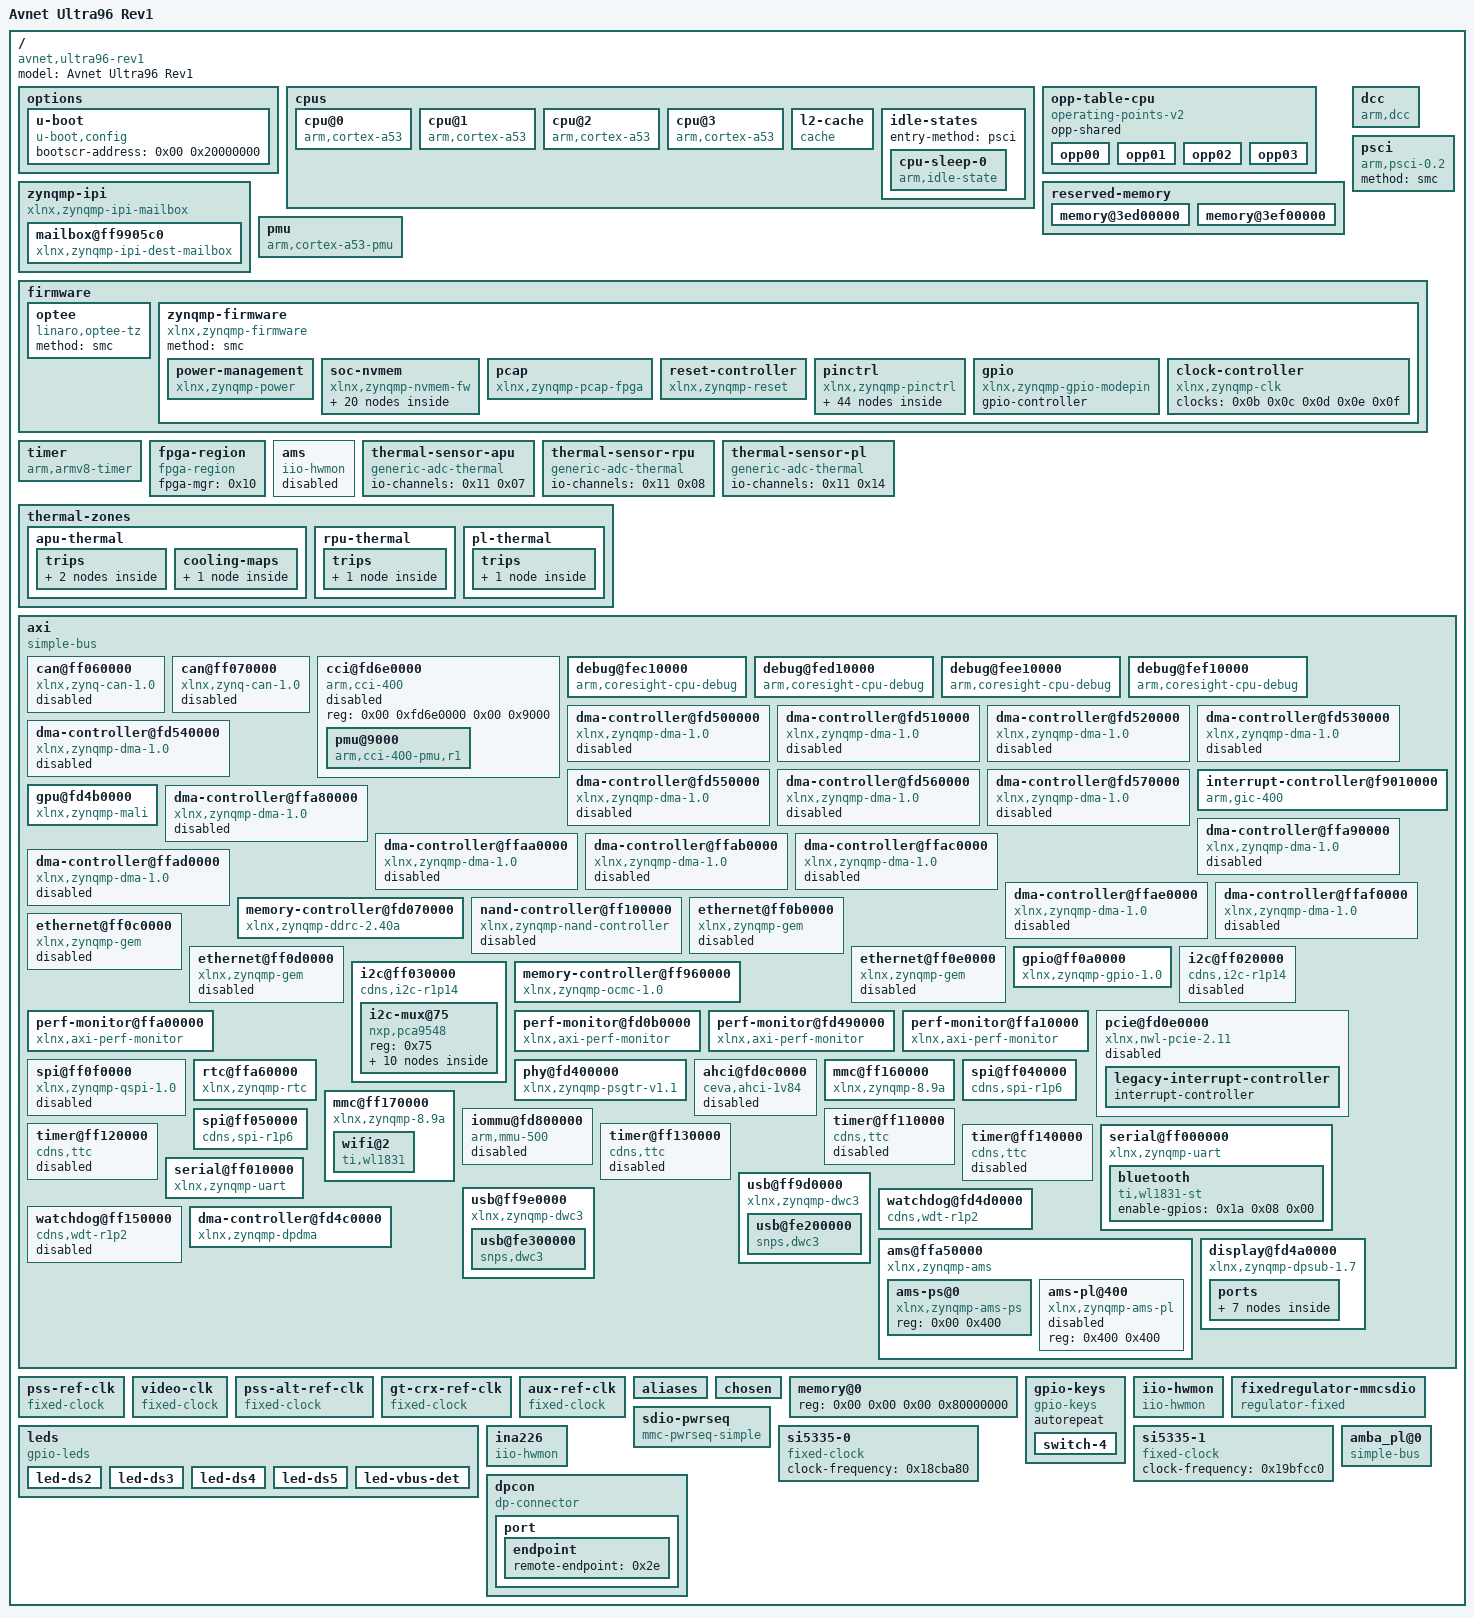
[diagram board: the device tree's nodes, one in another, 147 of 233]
/dts-v1/;

/ {
	compatible = "avnet,ultra96-rev1\0avnet,ultra96\0xlnx,zynqmp-zcu100-revC\0xlnx,zynqmp-zcu100\0xlnx,zynqmp";
	#address-cells = <0x02>;
	#size-cells = <0x02>;
	model = "Avnet Ultra96 Rev1";

	options {

		u-boot {
			compatible = "u-boot,config";
			bootscr-address = <0x00 0x20000000>;
		};
	};

	cpus {
		#address-cells = <0x01>;
		#size-cells = <0x00>;

		cpu@0 {
			#cooling-cells = <0x02>;
			compatible = "arm,cortex-a53";
			device_type = "cpu";
			enable-method = "psci";
			operating-points-v2 = <0x01>;
			reg = <0x00>;
			cpu-idle-states = <0x02>;
			next-level-cache = <0x03>;
			clocks = <0x04 0x0a>;
			phandle = <0x06>;
		};

		cpu@1 {
			#cooling-cells = <0x02>;
			compatible = "arm,cortex-a53";
			device_type = "cpu";
			enable-method = "psci";
			reg = <0x01>;
			operating-points-v2 = <0x01>;
			cpu-idle-states = <0x02>;
			next-level-cache = <0x03>;
			phandle = <0x07>;
		};

		cpu@2 {
			#cooling-cells = <0x02>;
			compatible = "arm,cortex-a53";
			device_type = "cpu";
			enable-method = "psci";
			reg = <0x02>;
			operating-points-v2 = <0x01>;
			cpu-idle-states = <0x02>;
			next-level-cache = <0x03>;
			phandle = <0x08>;
		};

		cpu@3 {
			#cooling-cells = <0x02>;
			compatible = "arm,cortex-a53";
			device_type = "cpu";
			enable-method = "psci";
			reg = <0x03>;
			operating-points-v2 = <0x01>;
			cpu-idle-states = <0x02>;
			next-level-cache = <0x03>;
			phandle = <0x09>;
		};

		l2-cache {
			compatible = "cache";
			cache-level = <0x02>;
			cache-unified;
			phandle = <0x03>;
		};

		idle-states {
			entry-method = "psci";

			cpu-sleep-0 {
				compatible = "arm,idle-state";
				arm,psci-suspend-param = <0x40000000>;
				local-timer-stop;
				entry-latency-us = <0x12c>;
				exit-latency-us = <0x258>;
				min-residency-us = <0x2710>;
				phandle = <0x02>;
			};
		};
	};

	opp-table-cpu {
		compatible = "operating-points-v2";
		opp-shared;
		phandle = <0x01>;

		opp00 {
			opp-hz = <0x00 0x47868bf4>;
			opp-microvolt = <0xf4240>;
			clock-latency-ns = <0x7a120>;
		};

		opp01 {
			opp-hz = <0x00 0x23c345fa>;
			opp-microvolt = <0xf4240>;
			clock-latency-ns = <0x7a120>;
		};

		opp02 {
			opp-hz = <0x00 0x17d783fc>;
			opp-microvolt = <0xf4240>;
			clock-latency-ns = <0x7a120>;
		};

		opp03 {
			opp-hz = <0x00 0x11e1a2fd>;
			opp-microvolt = <0xf4240>;
			clock-latency-ns = <0x7a120>;
		};
	};

	reserved-memory {
		#address-cells = <0x02>;
		#size-cells = <0x02>;
		ranges;

		memory@3ed00000 {
			no-map;
			reg = <0x00 0x3ed00000 0x00 0x40000>;
			phandle = <0x2f>;
		};

		memory@3ef00000 {
			no-map;
			reg = <0x00 0x3ef00000 0x00 0x40000>;
			phandle = <0x30>;
		};
	};

	zynqmp-ipi {
		bootph-all;
		compatible = "xlnx,zynqmp-ipi-mailbox";
		interrupt-parent = <0x05>;
		interrupts = <0x00 0x23 0x04>;
		xlnx,ipi-id = <0x00>;
		#address-cells = <0x02>;
		#size-cells = <0x02>;
		ranges;
		phandle = <0x31>;

		mailbox@ff9905c0 {
			bootph-all;
			compatible = "xlnx,zynqmp-ipi-dest-mailbox";
			reg = <0x00 0xff9905c0 0x00 0x20 0x00 0xff9905e0 0x00 0x20 0x00 0xff990e80 0x00 0x20 0x00 0xff990ea0 0x00 0x20>;
			reg-names = "local_request_region\0local_response_region\0remote_request_region\0remote_response_region";
			#mbox-cells = <0x01>;
			xlnx,ipi-id = <0x04>;
			phandle = <0x0a>;
		};
	};

	dcc {
		compatible = "arm,dcc";
		status = "okay";
		bootph-all;
		phandle = <0x32>;
	};

	pmu {
		compatible = "arm,cortex-a53-pmu";
		interrupt-parent = <0x05>;
		interrupts = <0x00 0x8f 0x04 0x00 0x90 0x04 0x00 0x91 0x04 0x00 0x92 0x04>;
		interrupt-affinity = <0x06 0x07 0x08 0x09>;
	};

	psci {
		compatible = "arm,psci-0.2";
		method = "smc";
	};

	firmware {

		optee {
			compatible = "linaro,optee-tz";
			method = "smc";
			phandle = <0x33>;
		};

		zynqmp-firmware {
			compatible = "xlnx,zynqmp-firmware";
			#power-domain-cells = <0x01>;
			method = "smc";
			bootph-all;
			phandle = <0x17>;

			power-management {
				bootph-all;
				compatible = "xlnx,zynqmp-power";
				interrupt-parent = <0x05>;
				interrupts = <0x00 0x23 0x04>;
				mboxes = <0x0a 0x00 0x0a 0x01>;
				mbox-names = "tx\0rx";
				phandle = <0x34>;
			};

			soc-nvmem {
				compatible = "xlnx,zynqmp-nvmem-fw";

				nvmem-layout {
					compatible = "fixed-layout";
					#address-cells = <0x01>;
					#size-cells = <0x01>;

					soc-revision@0 {
						reg = <0x00 0x04>;
						phandle = <0x35>;
					};

					efuse-dna@c {
						reg = <0x0c 0x0c>;
						phandle = <0x36>;
					};

					efuse-usr0@20 {
						reg = <0x20 0x04>;
						phandle = <0x37>;
					};

					efuse-usr1@24 {
						reg = <0x24 0x04>;
						phandle = <0x38>;
					};

					efuse-usr2@28 {
						reg = <0x28 0x04>;
						phandle = <0x39>;
					};

					efuse-usr3@2c {
						reg = <0x2c 0x04>;
						phandle = <0x3a>;
					};

					efuse-usr4@30 {
						reg = <0x30 0x04>;
						phandle = <0x3b>;
					};

					efuse-usr5@34 {
						reg = <0x34 0x04>;
						phandle = <0x3c>;
					};

					efuse-usr6@38 {
						reg = <0x38 0x04>;
						phandle = <0x3d>;
					};

					efuse-usr7@3c {
						reg = <0x3c 0x04>;
						phandle = <0x3e>;
					};

					efuse-miscusr@40 {
						reg = <0x40 0x04>;
						phandle = <0x3f>;
					};

					efuse-chash@50 {
						reg = <0x50 0x04>;
						phandle = <0x40>;
					};

					efuse-pufmisc@54 {
						reg = <0x54 0x04>;
						phandle = <0x41>;
					};

					efuse-sec@58 {
						reg = <0x58 0x04>;
						phandle = <0x42>;
					};

					efuse-spkid@5c {
						reg = <0x5c 0x04>;
						phandle = <0x43>;
					};

					efuse-aeskey@60 {
						reg = <0x60 0x20>;
						phandle = <0x44>;
					};

					efuse-ppk0hash@a0 {
						reg = <0xa0 0x30>;
						phandle = <0x45>;
					};

					efuse-ppk1hash@d0 {
						reg = <0xd0 0x30>;
						phandle = <0x46>;
					};

					efuse-pufuser@100 {
						reg = <0x100 0x7f>;
						phandle = <0x47>;
					};
				};
			};

			pcap {
				compatible = "xlnx,zynqmp-pcap-fpga";
				phandle = <0x10>;
			};

			reset-controller {
				compatible = "xlnx,zynqmp-reset";
				#reset-cells = <0x01>;
				phandle = <0x16>;
			};

			pinctrl {
				compatible = "xlnx,zynqmp-pinctrl";
				status = "okay";
				phandle = <0x48>;

				i2c1-default {
					phandle = <0x18>;

					mux {
						groups = "i2c1_1_grp";
						function = "i2c1";
					};

					conf {
						groups = "i2c1_1_grp";
						bias-pull-up;
						slew-rate = <0x01>;
						power-source = <0x01>;
					};
				};

				i2c1-gpio-grp {
					phandle = <0x19>;

					mux {
						groups = "gpio0_4_grp\0gpio0_5_grp";
						function = "gpio0";
					};

					conf {
						groups = "gpio0_4_grp\0gpio0_5_grp";
						slew-rate = <0x01>;
						power-source = <0x01>;
					};
				};

				sdhci0-default {
					phandle = <0x1f>;

					mux {
						groups = "sdio0_3_grp";
						function = "sdio0";
					};

					conf {
						groups = "sdio0_3_grp";
						slew-rate = <0x01>;
						power-source = <0x01>;
						bias-disable;
					};

					mux-cd {
						groups = "sdio0_cd_0_grp";
						function = "sdio0_cd";
					};

					conf-cd {
						groups = "sdio0_cd_0_grp";
						bias-high-impedance;
						bias-pull-up;
						slew-rate = <0x01>;
						power-source = <0x01>;
					};
				};

				sdhci1-default {
					phandle = <0x20>;

					mux {
						groups = "sdio1_2_grp";
						function = "sdio1";
					};

					conf {
						groups = "sdio1_2_grp";
						slew-rate = <0x01>;
						power-source = <0x01>;
						bias-disable;
					};
				};

				spi0-default {
					phandle = <0x23>;

					mux {
						groups = "spi0_3_grp";
						function = "spi0";
					};

					conf {
						groups = "spi0_3_grp";
						bias-disable;
						slew-rate = <0x01>;
						power-source = <0x01>;
					};

					mux-cs {
						groups = "spi0_ss_9_grp";
						function = "spi0_ss";
					};

					conf-cs {
						groups = "spi0_ss_9_grp";
						bias-disable;
					};
				};

				spi1-default {
					phandle = <0x24>;

					mux {
						groups = "spi1_0_grp";
						function = "spi1";
					};

					conf {
						groups = "spi1_0_grp";
						bias-disable;
						slew-rate = <0x01>;
						power-source = <0x01>;
					};

					mux-cs {
						groups = "spi1_ss_0_grp";
						function = "spi1_ss";
					};

					conf-cs {
						groups = "spi1_ss_0_grp";
						bias-disable;
					};
				};

				uart0-default {
					phandle = <0x25>;

					mux {
						groups = "uart0_0_grp";
						function = "uart0";
					};

					conf {
						groups = "uart0_0_grp";
						slew-rate = <0x01>;
						power-source = <0x01>;
					};

					conf-rx {
						pins = "MIO3";
						bias-high-impedance;
					};

					conf-tx {
						pins = "MIO2";
						bias-disable;
					};
				};

				uart1-default {
					phandle = <0x26>;

					mux {
						groups = "uart1_0_grp";
						function = "uart1";
					};

					conf {
						groups = "uart1_0_grp";
						slew-rate = <0x01>;
						power-source = <0x01>;
					};

					conf-rx {
						pins = "MIO1";
						bias-high-impedance;
					};

					conf-tx {
						pins = "MIO0";
						bias-disable;
					};
				};

				usb0-default {
					phandle = <0x27>;

					mux {
						groups = "usb0_0_grp";
						function = "usb0";
					};

					conf {
						groups = "usb0_0_grp";
						power-source = <0x01>;
					};

					conf-rx {
						pins = "MIO52\0MIO53\0MIO55";
						bias-high-impedance;
						drive-strength = <0x0c>;
						slew-rate = <0x00>;
					};

					conf-tx {
						pins = "MIO54\0MIO56\0MIO57\0MIO58\0MIO59\0MIO60\0MIO61\0MIO62\0MIO63";
						bias-disable;
						drive-strength = <0x04>;
						slew-rate = <0x01>;
					};
				};

				usb1-default {
					phandle = <0x29>;

					mux {
						groups = "usb1_0_grp";
						function = "usb1";
					};

					conf {
						groups = "usb1_0_grp";
						power-source = <0x01>;
					};

					conf-rx {
						pins = "MIO64\0MIO65\0MIO67";
						bias-high-impedance;
						drive-strength = <0x0c>;
						slew-rate = <0x00>;
					};

					conf-tx {
						pins = "MIO66\0MIO68\0MIO69\0MIO70\0MIO71\0MIO72\0MIO73\0MIO74\0MIO75";
						bias-disable;
						drive-strength = <0x04>;
						slew-rate = <0x01>;
					};
				};
			};

			gpio {
				compatible = "xlnx,zynqmp-gpio-modepin";
				gpio-controller;
				#gpio-cells = <0x02>;
				phandle = <0x2a>;
			};

			clock-controller {
				bootph-all;
				#clock-cells = <0x01>;
				compatible = "xlnx,zynqmp-clk";
				clocks = <0x0b 0x0c 0x0d 0x0e 0x0f>;
				clock-names = "pss_ref_clk\0video_clk\0pss_alt_ref_clk\0aux_ref_clk\0gt_crx_ref_clk";
				phandle = <0x04>;
			};
		};
	};

	timer {
		compatible = "arm,armv8-timer";
		interrupt-parent = <0x05>;
		interrupts = <0x01 0x0d 0xf08 0x01 0x0e 0xf08 0x01 0x0b 0xf08 0x01 0x0a 0xf08>;
	};

	fpga-region {
		compatible = "fpga-region";
		fpga-mgr = <0x10>;
		#address-cells = <0x02>;
		#size-cells = <0x02>;
		ranges;
		phandle = <0x49>;
	};

	ams {
		compatible = "iio-hwmon";
		status = "disabled";
		io-channels = <0x11 0x00 0x11 0x01 0x11 0x02 0x11 0x03 0x11 0x04 0x11 0x05 0x11 0x06 0x11 0x07 0x11 0x08 0x11 0x09 0x11 0x0a 0x11 0x0b 0x11 0x0c 0x11 0x0d 0x11 0x0e 0x11 0x0f 0x11 0x10 0x11 0x11 0x11 0x12 0x11 0x13 0x11 0x14 0x11 0x15 0x11 0x16 0x11 0x17 0x11 0x18 0x11 0x19 0x11 0x1a 0x11 0x1b 0x11 0x1c 0x11 0x1d>;
		phandle = <0x4a>;
	};

	thermal-sensor-apu {
		compatible = "generic-adc-thermal";
		#thermal-sensor-cells = <0x00>;
		io-channels = <0x11 0x07>;
		io-channel-names = "sensor-channel";
		phandle = <0x12>;
	};

	thermal-sensor-rpu {
		compatible = "generic-adc-thermal";
		#thermal-sensor-cells = <0x00>;
		io-channels = <0x11 0x08>;
		io-channel-names = "sensor-channel";
		phandle = <0x14>;
	};

	thermal-sensor-pl {
		compatible = "generic-adc-thermal";
		#thermal-sensor-cells = <0x00>;
		io-channels = <0x11 0x14>;
		io-channel-names = "sensor-channel";
		phandle = <0x15>;
	};

	thermal-zones {

		apu-thermal {
			polling-delay-passive = <0x3e8>;
			polling-delay = <0x1388>;
			thermal-sensors = <0x12>;

			trips {

				passive {
					temperature = <0x16b48>;
					hysteresis = <0xdac>;
					type = "passive";
					phandle = <0x13>;
				};

				critical {
					temperature = <0x178f4>;
					hysteresis = <0xdac>;
					type = "critical";
					phandle = <0x4b>;
				};
			};

			cooling-maps {

				map {
					trip = <0x13>;
					cooling-device = <0x06 0xffffffff 0xffffffff 0x07 0xffffffff 0xffffffff 0x08 0xffffffff 0xffffffff 0x09 0xffffffff 0xffffffff>;
				};
			};
		};

		rpu-thermal {
			polling-delay = <0x2710>;
			thermal-sensors = <0x14>;

			trips {

				critical {
					temperature = <0x178f4>;
					hysteresis = <0xdac>;
					type = "critical";
				};
			};
		};

		pl-thermal {
			polling-delay = <0x2710>;
			thermal-sensors = <0x15>;

			trips {

				critical {
					temperature = <0x178f4>;
					hysteresis = <0xdac>;
					type = "critical";
				};
			};
		};
	};

	axi {
		compatible = "simple-bus";
		bootph-all;
		#address-cells = <0x02>;
		#size-cells = <0x02>;
		ranges;
		phandle = <0x4c>;

		can@ff060000 {
			compatible = "xlnx,zynq-can-1.0";
			status = "disabled";
			clock-names = "can_clk\0pclk";
			reg = <0x00 0xff060000 0x00 0x1000>;
			interrupts = <0x00 0x17 0x04>;
			interrupt-parent = <0x05>;
			tx-fifo-depth = <0x40>;
			rx-fifo-depth = <0x40>;
			resets = <0x16 0x28>;
			power-domains = <0x17 0x2f>;
			clocks = <0x04 0x3f 0x04 0x1f>;
			phandle = <0x4d>;
		};

		can@ff070000 {
			compatible = "xlnx,zynq-can-1.0";
			status = "disabled";
			clock-names = "can_clk\0pclk";
			reg = <0x00 0xff070000 0x00 0x1000>;
			interrupts = <0x00 0x18 0x04>;
			interrupt-parent = <0x05>;
			tx-fifo-depth = <0x40>;
			rx-fifo-depth = <0x40>;
			resets = <0x16 0x29>;
			power-domains = <0x17 0x30>;
			clocks = <0x04 0x40 0x04 0x1f>;
			phandle = <0x4e>;
		};

		cci@fd6e0000 {
			compatible = "arm,cci-400";
			status = "disabled";
			reg = <0x00 0xfd6e0000 0x00 0x9000>;
			ranges = <0x00 0x00 0xfd6e0000 0x10000>;
			#address-cells = <0x01>;
			#size-cells = <0x01>;
			phandle = <0x4f>;

			pmu@9000 {
				compatible = "arm,cci-400-pmu,r1";
				reg = <0x9000 0x5000>;
				interrupt-parent = <0x05>;
				interrupts = <0x00 0x7b 0x04 0x00 0x7b 0x04 0x00 0x7b 0x04 0x00 0x7b 0x04 0x00 0x7b 0x04>;
			};
		};

		debug@fec10000 {
			compatible = "arm,coresight-cpu-debug\0arm,primecell";
			reg = <0x00 0xfec10000 0x00 0x1000>;
			clock-names = "apb_pclk";
			cpu = <0x06>;
			clocks = <0x04 0x0c>;
			phandle = <0x50>;
		};

		debug@fed10000 {
			compatible = "arm,coresight-cpu-debug\0arm,primecell";
			reg = <0x00 0xfed10000 0x00 0x1000>;
			clock-names = "apb_pclk";
			cpu = <0x07>;
			clocks = <0x04 0x0c>;
			phandle = <0x51>;
		};

		debug@fee10000 {
			compatible = "arm,coresight-cpu-debug\0arm,primecell";
			reg = <0x00 0xfee10000 0x00 0x1000>;
			clock-names = "apb_pclk";
			cpu = <0x08>;
			clocks = <0x04 0x0c>;
			phandle = <0x52>;
		};

		debug@fef10000 {
			compatible = "arm,coresight-cpu-debug\0arm,primecell";
			reg = <0x00 0xfef10000 0x00 0x1000>;
			clock-names = "apb_pclk";
			cpu = <0x09>;
			clocks = <0x04 0x0c>;
			phandle = <0x53>;
		};

		dma-controller@fd500000 {
			status = "disabled";
			compatible = "xlnx,zynqmp-dma-1.0";
			reg = <0x00 0xfd500000 0x00 0x1000>;
			interrupt-parent = <0x05>;
			interrupts = <0x00 0x7c 0x04>;
			clock-names = "clk_main\0clk_apb";
			#dma-cells = <0x01>;
			xlnx,bus-width = <0x80>;
			power-domains = <0x17 0x2a>;
			clocks = <0x04 0x13 0x04 0x1f>;
			phandle = <0x54>;
		};

		dma-controller@fd510000 {
			status = "disabled";
			compatible = "xlnx,zynqmp-dma-1.0";
			reg = <0x00 0xfd510000 0x00 0x1000>;
			interrupt-parent = <0x05>;
			interrupts = <0x00 0x7d 0x04>;
			clock-names = "clk_main\0clk_apb";
			#dma-cells = <0x01>;
			xlnx,bus-width = <0x80>;
			power-domains = <0x17 0x2a>;
			clocks = <0x04 0x13 0x04 0x1f>;
			phandle = <0x55>;
		};

		dma-controller@fd520000 {
			status = "disabled";
			compatible = "xlnx,zynqmp-dma-1.0";
			reg = <0x00 0xfd520000 0x00 0x1000>;
			interrupt-parent = <0x05>;
			interrupts = <0x00 0x7e 0x04>;
			clock-names = "clk_main\0clk_apb";
			#dma-cells = <0x01>;
			xlnx,bus-width = <0x80>;
			power-domains = <0x17 0x2a>;
			clocks = <0x04 0x13 0x04 0x1f>;
			phandle = <0x56>;
		};

		dma-controller@fd530000 {
			status = "disabled";
			compatible = "xlnx,zynqmp-dma-1.0";
			reg = <0x00 0xfd530000 0x00 0x1000>;
			interrupt-parent = <0x05>;
			interrupts = <0x00 0x7f 0x04>;
			clock-names = "clk_main\0clk_apb";
			#dma-cells = <0x01>;
			xlnx,bus-width = <0x80>;
			power-domains = <0x17 0x2a>;
			clocks = <0x04 0x13 0x04 0x1f>;
			phandle = <0x57>;
		};

		dma-controller@fd540000 {
			status = "disabled";
			compatible = "xlnx,zynqmp-dma-1.0";
			reg = <0x00 0xfd540000 0x00 0x1000>;
			interrupt-parent = <0x05>;
			interrupts = <0x00 0x80 0x04>;
			clock-names = "clk_main\0clk_apb";
			#dma-cells = <0x01>;
			xlnx,bus-width = <0x80>;
			power-domains = <0x17 0x2a>;
			clocks = <0x04 0x13 0x04 0x1f>;
			phandle = <0x58>;
		};

		dma-controller@fd550000 {
			status = "disabled";
			compatible = "xlnx,zynqmp-dma-1.0";
			reg = <0x00 0xfd550000 0x00 0x1000>;
			interrupt-parent = <0x05>;
			interrupts = <0x00 0x81 0x04>;
			clock-names = "clk_main\0clk_apb";
			#dma-cells = <0x01>;
			xlnx,bus-width = <0x80>;
			power-domains = <0x17 0x2a>;
			clocks = <0x04 0x13 0x04 0x1f>;
			phandle = <0x59>;
		};

		dma-controller@fd560000 {
			status = "disabled";
			compatible = "xlnx,zynqmp-dma-1.0";
			reg = <0x00 0xfd560000 0x00 0x1000>;
			interrupt-parent = <0x05>;
			interrupts = <0x00 0x82 0x04>;
			clock-names = "clk_main\0clk_apb";
			#dma-cells = <0x01>;
			xlnx,bus-width = <0x80>;
			power-domains = <0x17 0x2a>;
			clocks = <0x04 0x13 0x04 0x1f>;
			phandle = <0x5a>;
		};

		dma-controller@fd570000 {
			status = "disabled";
			compatible = "xlnx,zynqmp-dma-1.0";
			reg = <0x00 0xfd570000 0x00 0x1000>;
			interrupt-parent = <0x05>;
			interrupts = <0x00 0x83 0x04>;
			clock-names = "clk_main\0clk_apb";
			#dma-cells = <0x01>;
			xlnx,bus-width = <0x80>;
			power-domains = <0x17 0x2a>;
			clocks = <0x04 0x13 0x04 0x1f>;
			phandle = <0x5b>;
		};

		interrupt-controller@f9010000 {
			compatible = "arm,gic-400";
			#interrupt-cells = <0x03>;
			reg = <0x00 0xf9010000 0x00 0x10000 0x00 0xf9020000 0x00 0x20000 0x00 0xf9040000 0x00 0x20000 0x00 0xf9060000 0x00 0x20000>;
			interrupt-controller;
			interrupt-parent = <0x05>;
			interrupts = <0x01 0x09 0xf04>;
			phandle = <0x05>;
		};

		gpu@fd4b0000 {
			status = "okay";
			compatible = "xlnx,zynqmp-mali\0arm,mali-400";
			reg = <0x00 0xfd4b0000 0x00 0x10000>;
			interrupt-parent = <0x05>;
			interrupts = <0x00 0x84 0x04 0x00 0x84 0x04 0x00 0x84 0x04 0x00 0x84 0x04 0x00 0x84 0x04 0x00 0x84 0x04>;
			interrupt-names = "gp\0gpmmu\0pp0\0ppmmu0\0pp1\0ppmmu1";
			clock-names = "bus\0core";
			power-domains = <0x17 0x3a>;
			clocks = <0x04 0x18 0x04 0x19>;
			phandle = <0x5c>;
		};

		dma-controller@ffa80000 {
			status = "disabled";
			compatible = "xlnx,zynqmp-dma-1.0";
			reg = <0x00 0xffa80000 0x00 0x1000>;
			interrupt-parent = <0x05>;
			interrupts = <0x00 0x4d 0x04>;
			clock-names = "clk_main\0clk_apb";
			#dma-cells = <0x01>;
			xlnx,bus-width = <0x40>;
			power-domains = <0x17 0x2b>;
			clocks = <0x04 0x44 0x04 0x1f>;
			phandle = <0x5d>;
		};

		dma-controller@ffa90000 {
			status = "disabled";
			compatible = "xlnx,zynqmp-dma-1.0";
			reg = <0x00 0xffa90000 0x00 0x1000>;
			interrupt-parent = <0x05>;
			interrupts = <0x00 0x4e 0x04>;
			clock-names = "clk_main\0clk_apb";
			#dma-cells = <0x01>;
			xlnx,bus-width = <0x40>;
			power-domains = <0x17 0x2b>;
			clocks = <0x04 0x44 0x04 0x1f>;
			phandle = <0x5e>;
		};

		dma-controller@ffaa0000 {
			status = "disabled";
			compatible = "xlnx,zynqmp-dma-1.0";
			reg = <0x00 0xffaa0000 0x00 0x1000>;
			interrupt-parent = <0x05>;
			interrupts = <0x00 0x4f 0x04>;
			clock-names = "clk_main\0clk_apb";
			#dma-cells = <0x01>;
			xlnx,bus-width = <0x40>;
			power-domains = <0x17 0x2b>;
			clocks = <0x04 0x44 0x04 0x1f>;
			phandle = <0x5f>;
		};

		dma-controller@ffab0000 {
			status = "disabled";
			compatible = "xlnx,zynqmp-dma-1.0";
			reg = <0x00 0xffab0000 0x00 0x1000>;
			interrupt-parent = <0x05>;
			interrupts = <0x00 0x50 0x04>;
			clock-names = "clk_main\0clk_apb";
			#dma-cells = <0x01>;
			xlnx,bus-width = <0x40>;
			power-domains = <0x17 0x2b>;
			clocks = <0x04 0x44 0x04 0x1f>;
			phandle = <0x60>;
		};

		dma-controller@ffac0000 {
			status = "disabled";
			compatible = "xlnx,zynqmp-dma-1.0";
			reg = <0x00 0xffac0000 0x00 0x1000>;
			interrupt-parent = <0x05>;
			interrupts = <0x00 0x51 0x04>;
			clock-names = "clk_main\0clk_apb";
			#dma-cells = <0x01>;
			xlnx,bus-width = <0x40>;
			power-domains = <0x17 0x2b>;
			clocks = <0x04 0x44 0x04 0x1f>;
			phandle = <0x61>;
		};

		dma-controller@ffad0000 {
			status = "disabled";
			compatible = "xlnx,zynqmp-dma-1.0";
			reg = <0x00 0xffad0000 0x00 0x1000>;
			interrupt-parent = <0x05>;
			interrupts = <0x00 0x52 0x04>;
			clock-names = "clk_main\0clk_apb";
			#dma-cells = <0x01>;
			xlnx,bus-width = <0x40>;
			power-domains = <0x17 0x2b>;
			clocks = <0x04 0x44 0x04 0x1f>;
			phandle = <0x62>;
		};

		dma-controller@ffae0000 {
			status = "disabled";
			compatible = "xlnx,zynqmp-dma-1.0";
			reg = <0x00 0xffae0000 0x00 0x1000>;
			interrupt-parent = <0x05>;
			interrupts = <0x00 0x53 0x04>;
			clock-names = "clk_main\0clk_apb";
			#dma-cells = <0x01>;
			xlnx,bus-width = <0x40>;
			power-domains = <0x17 0x2b>;
			clocks = <0x04 0x44 0x04 0x1f>;
			phandle = <0x63>;
		};

		dma-controller@ffaf0000 {
			status = "disabled";
			compatible = "xlnx,zynqmp-dma-1.0";
			reg = <0x00 0xffaf0000 0x00 0x1000>;
			interrupt-parent = <0x05>;
			interrupts = <0x00 0x54 0x04>;
			clock-names = "clk_main\0clk_apb";
			#dma-cells = <0x01>;
			xlnx,bus-width = <0x40>;
			power-domains = <0x17 0x2b>;
			clocks = <0x04 0x44 0x04 0x1f>;
			phandle = <0x64>;
		};

		memory-controller@fd070000 {
			compatible = "xlnx,zynqmp-ddrc-2.40a";
			reg = <0x00 0xfd070000 0x00 0x30000>;
			interrupt-parent = <0x05>;
			interrupts = <0x00 0x70 0x04>;
			phandle = <0x65>;
		};

		nand-controller@ff100000 {
			compatible = "xlnx,zynqmp-nand-controller\0arasan,nfc-v3p10";
			status = "disabled";
			reg = <0x00 0xff100000 0x00 0x1000>;
			clock-names = "controller\0bus";
			interrupt-parent = <0x05>;
			interrupts = <0x00 0x0e 0x04>;
			#address-cells = <0x01>;
			#size-cells = <0x00>;
			power-domains = <0x17 0x2c>;
			clocks = <0x04 0x3c 0x04 0x1f>;
			phandle = <0x66>;
		};

		ethernet@ff0b0000 {
			compatible = "xlnx,zynqmp-gem\0cdns,gem";
			status = "disabled";
			interrupt-parent = <0x05>;
			interrupts = <0x00 0x39 0x04 0x00 0x39 0x04>;
			reg = <0x00 0xff0b0000 0x00 0x1000>;
			clock-names = "pclk\0hclk\0tx_clk\0rx_clk\0tsu_clk";
			power-domains = <0x17 0x1d>;
			resets = <0x16 0x1d>;
			reset-names = "gem0_rst";
			clocks = <0x04 0x1f 0x04 0x68 0x04 0x2d 0x04 0x31 0x04 0x2c>;
			assigned-clocks = <0x04 0x2c>;
			phandle = <0x67>;
		};

		ethernet@ff0c0000 {
			compatible = "xlnx,zynqmp-gem\0cdns,gem";
			status = "disabled";
			interrupt-parent = <0x05>;
			interrupts = <0x00 0x3b 0x04 0x00 0x3b 0x04>;
			reg = <0x00 0xff0c0000 0x00 0x1000>;
			clock-names = "pclk\0hclk\0tx_clk\0rx_clk\0tsu_clk";
			power-domains = <0x17 0x1e>;
			resets = <0x16 0x1e>;
			reset-names = "gem1_rst";
			clocks = <0x04 0x1f 0x04 0x69 0x04 0x2e 0x04 0x32 0x04 0x2c>;
			assigned-clocks = <0x04 0x2c>;
			phandle = <0x68>;
		};

		ethernet@ff0d0000 {
			compatible = "xlnx,zynqmp-gem\0cdns,gem";
			status = "disabled";
			interrupt-parent = <0x05>;
			interrupts = <0x00 0x3d 0x04 0x00 0x3d 0x04>;
			reg = <0x00 0xff0d0000 0x00 0x1000>;
			clock-names = "pclk\0hclk\0tx_clk\0rx_clk\0tsu_clk";
			power-domains = <0x17 0x1f>;
			resets = <0x16 0x1f>;
			reset-names = "gem2_rst";
			clocks = <0x04 0x1f 0x04 0x6a 0x04 0x2f 0x04 0x33 0x04 0x2c>;
			assigned-clocks = <0x04 0x2c>;
			phandle = <0x69>;
		};

		ethernet@ff0e0000 {
			compatible = "xlnx,zynqmp-gem\0cdns,gem";
			status = "disabled";
			interrupt-parent = <0x05>;
			interrupts = <0x00 0x3f 0x04 0x00 0x3f 0x04>;
			reg = <0x00 0xff0e0000 0x00 0x1000>;
			clock-names = "pclk\0hclk\0tx_clk\0rx_clk\0tsu_clk";
			power-domains = <0x17 0x20>;
			resets = <0x16 0x20>;
			reset-names = "gem3_rst";
			clocks = <0x04 0x1f 0x04 0x6b 0x04 0x30 0x04 0x34 0x04 0x2c>;
			assigned-clocks = <0x04 0x2c>;
			phandle = <0x6a>;
		};

		gpio@ff0a0000 {
			compatible = "xlnx,zynqmp-gpio-1.0";
			status = "okay";
			#gpio-cells = <0x02>;
			gpio-controller;
			interrupt-parent = <0x05>;
			interrupts = <0x00 0x10 0x04>;
			interrupt-controller;
			#interrupt-cells = <0x02>;
			reg = <0x00 0xff0a0000 0x00 0x1000>;
			power-domains = <0x17 0x2e>;
			clocks = <0x04 0x1f>;
			gpio-line-names = "UART1_TX\0UART1_RX\0UART0_RX\0UART0_TX\0I2C1_SCL\0I2C1_SDA\0SPI1_SCLK\0WLAN_EN\0BT_EN\0SPI1_CS\0SPI1_MISO\0SPI1_MOSI\0I2C_MUX_RESET\0SD0_DAT0\0SD0_DAT1\0SD0_DAT2\0SD0_DAT3\0PS_LED3\0PS_LED2\0PS_LED1\0PS_LED0\0SD0_CMD\0SD0_CLK\0GPIO_PB\0SD0_DETECT\0VBUS_DET\0POWER_INT\0DP_AUX\0DP_HPD\0DP_OE\0DP_AUX_IN\0INA226_ALERT\0PS_FP_PWR_EN\0PL_PWR_EN\0POWER_KILL\0\0GPIO-A\0GPIO-B\0SPI0_SCLK\0GPIO-C\0GPIO-D\0SPI0_CS\0SPI0_MISO\0SPI_MOSI\0GPIO-E\0GPIO-F\0SD1_D0\0SD1_D1\0SD1_D2\0SD1_D3\0SD1_CMD\0SD1_CLK\0USB0_CLK\0USB0_DIR\0USB0_DATA2\0USB0_NXT\0USB0_DATA0\0USB0_DATA1\0USB0_STP\0USB0_DATA3\0USB0_DATA4\0USB0_DATA5\0USB0_DATA6\0USB0_DATA7\0USB1_CLK\0USB1_DIR\0USB1_DATA2\0USB1_NXT\0USB1_DATA0\0USB1_DATA1\0USB1_STP\0USB1_DATA3\0USB1_DATA4\0USB1_DATA5\0USB1_DATA6\0USB_DATA7\0WLAN_IRQ\0PMIC_IRQ\0\0\0\0\0\0\0\0\0\0\0\0\0\0\0\0\0\0\0\0\0\0\0\0\0\0\0\0\0\0\0\0\0\0\0\0\0\0\0\0\0\0\0\0\0\0\0\0\0\0\0\0\0\0\0\0\0\0\0\0\0\0\0\0\0\0\0\0\0\0\0\0\0\0\0\0\0\0\0\0\0\0\0\0\0\0\0\0\0\0\0\0\0\0\0\0";
			phandle = <0x1a>;
		};

		i2c@ff020000 {
			compatible = "cdns,i2c-r1p14";
			status = "disabled";
			interrupt-parent = <0x05>;
			interrupts = <0x00 0x11 0x04>;
			clock-frequency = <0x61a80>;
			reg = <0x00 0xff020000 0x00 0x1000>;
			#address-cells = <0x01>;
			#size-cells = <0x00>;
			power-domains = <0x17 0x25>;
			clocks = <0x04 0x3d>;
			phandle = <0x6b>;
		};

		i2c@ff030000 {
			compatible = "cdns,i2c-r1p14";
			status = "okay";
			interrupt-parent = <0x05>;
			interrupts = <0x00 0x12 0x04>;
			clock-frequency = <0x186a0>;
			reg = <0x00 0xff030000 0x00 0x1000>;
			#address-cells = <0x01>;
			#size-cells = <0x00>;
			power-domains = <0x17 0x26>;
			clocks = <0x04 0x3e>;
			pinctrl-names = "default\0gpio";
			pinctrl-0 = <0x18>;
			pinctrl-1 = <0x19>;
			scl-gpios = <0x1a 0x04 0x06>;
			sda-gpios = <0x1a 0x05 0x06>;
			phandle = <0x6c>;

			i2c-mux@75 {
				compatible = "nxp,pca9548";
				#address-cells = <0x01>;
				#size-cells = <0x00>;
				reg = <0x75>;

				i2c@0 {
					#address-cells = <0x01>;
					#size-cells = <0x00>;
					reg = <0x00>;
					label = "LS-I2C0";
					phandle = <0x6d>;
				};

				i2c@1 {
					#address-cells = <0x01>;
					#size-cells = <0x00>;
					reg = <0x01>;
					label = "LS-I2C1";
					phandle = <0x6e>;
				};

				i2c@2 {
					#address-cells = <0x01>;
					#size-cells = <0x00>;
					reg = <0x02>;
					label = "HS-I2C2";
					phandle = <0x6f>;
				};

				i2c@3 {
					#address-cells = <0x01>;
					#size-cells = <0x00>;
					reg = <0x03>;
					label = "HS-I2C3";
					phandle = <0x70>;
				};

				i2c@4 {
					#address-cells = <0x01>;
					#size-cells = <0x00>;
					reg = <0x04>;
					phandle = <0x71>;

					pmic@5e {
						compatible = "ti,tps65086";
						reg = <0x5e>;
						interrupt-parent = <0x1a>;
						interrupts = <0x4d 0x08>;
						#gpio-cells = <0x02>;
						gpio-controller;
						phandle = <0x72>;
					};
				};

				i2c@5 {
					#address-cells = <0x01>;
					#size-cells = <0x00>;
					reg = <0x05>;
					phandle = <0x73>;

					ina226@40 {
						compatible = "ti,ina226";
						#io-channel-cells = <0x01>;
						reg = <0x40>;
						shunt-resistor = <0x2710>;
						phandle = <0x2d>;
					};
				};

				i2c@6 {
					#address-cells = <0x01>;
					#size-cells = <0x00>;
					reg = <0x06>;
					phandle = <0x74>;
				};

				i2c@7 {
					#address-cells = <0x01>;
					#size-cells = <0x00>;
					reg = <0x07>;
					phandle = <0x75>;
				};
			};
		};

		memory-controller@ff960000 {
			compatible = "xlnx,zynqmp-ocmc-1.0";
			reg = <0x00 0xff960000 0x00 0x1000>;
			interrupt-parent = <0x05>;
			interrupts = <0x00 0x0a 0x04>;
			phandle = <0x76>;
		};

		perf-monitor@ffa00000 {
			compatible = "xlnx,axi-perf-monitor";
			reg = <0x00 0xffa00000 0x00 0x10000>;
			interrupts = <0x00 0x19 0x04>;
			interrupt-parent = <0x05>;
			xlnx,enable-profile = <0x00>;
			xlnx,enable-trace = <0x00>;
			xlnx,num-monitor-slots = <0x01>;
			xlnx,enable-event-count = <0x01>;
			xlnx,enable-event-log = <0x01>;
			xlnx,have-sampled-metric-cnt = <0x01>;
			xlnx,num-of-counters = <0x08>;
			xlnx,metric-count-width = <0x20>;
			xlnx,metrics-sample-count-width = <0x20>;
			xlnx,global-count-width = <0x20>;
			xlnx,metric-count-scale = <0x01>;
			clocks = <0x04 0x1f>;
			phandle = <0x77>;
		};

		perf-monitor@fd0b0000 {
			compatible = "xlnx,axi-perf-monitor";
			reg = <0x00 0xfd0b0000 0x00 0x10000>;
			interrupts = <0x00 0x7b 0x04>;
			interrupt-parent = <0x05>;
			xlnx,enable-profile = <0x00>;
			xlnx,enable-trace = <0x00>;
			xlnx,num-monitor-slots = <0x06>;
			xlnx,enable-event-count = <0x01>;
			xlnx,enable-event-log = <0x00>;
			xlnx,have-sampled-metric-cnt = <0x01>;
			xlnx,num-of-counters = <0x0a>;
			xlnx,metric-count-width = <0x20>;
			xlnx,metrics-sample-count-width = <0x20>;
			xlnx,global-count-width = <0x20>;
			xlnx,metric-count-scale = <0x01>;
			clocks = <0x04 0x1c>;
			phandle = <0x78>;
		};

		perf-monitor@fd490000 {
			compatible = "xlnx,axi-perf-monitor";
			reg = <0x00 0xfd490000 0x00 0x10000>;
			interrupts = <0x00 0x7b 0x04>;
			interrupt-parent = <0x05>;
			xlnx,enable-profile = <0x00>;
			xlnx,enable-trace = <0x00>;
			xlnx,num-monitor-slots = <0x01>;
			xlnx,enable-event-count = <0x01>;
			xlnx,enable-event-log = <0x00>;
			xlnx,have-sampled-metric-cnt = <0x01>;
			xlnx,num-of-counters = <0x08>;
			xlnx,metric-count-width = <0x20>;
			xlnx,metrics-sample-count-width = <0x20>;
			xlnx,global-count-width = <0x20>;
			xlnx,metric-count-scale = <0x01>;
			clocks = <0x04 0x1c>;
			phandle = <0x79>;
		};

		perf-monitor@ffa10000 {
			compatible = "xlnx,axi-perf-monitor";
			reg = <0x00 0xffa10000 0x00 0x10000>;
			interrupts = <0x00 0x19 0x04>;
			interrupt-parent = <0x05>;
			xlnx,enable-profile = <0x00>;
			xlnx,enable-trace = <0x00>;
			xlnx,num-monitor-slots = <0x01>;
			xlnx,enable-event-count = <0x01>;
			xlnx,enable-event-log = <0x01>;
			xlnx,have-sampled-metric-cnt = <0x01>;
			xlnx,num-of-counters = <0x08>;
			xlnx,metric-count-width = <0x20>;
			xlnx,metrics-sample-count-width = <0x20>;
			xlnx,global-count-width = <0x20>;
			xlnx,metric-count-scale = <0x01>;
			clocks = <0x04 0x1f>;
			phandle = <0x7a>;
		};

		pcie@fd0e0000 {
			compatible = "xlnx,nwl-pcie-2.11";
			status = "disabled";
			#address-cells = <0x03>;
			#size-cells = <0x02>;
			#interrupt-cells = <0x01>;
			msi-controller;
			device_type = "pci";
			interrupt-parent = <0x05>;
			interrupts = <0x00 0x76 0x04 0x00 0x75 0x04 0x00 0x74 0x04 0x00 0x73 0x04 0x00 0x72 0x04>;
			interrupt-names = "misc\0dummy\0intx\0msi1\0msi0";
			msi-parent = <0x1b>;
			reg = <0x00 0xfd0e0000 0x00 0x1000 0x00 0xfd480000 0x00 0x1000 0x80 0x00 0x00 0x10000000>;
			reg-names = "breg\0pcireg\0cfg";
			ranges = <0x2000000 0x00 0xe0000000 0x00 0xe0000000 0x00 0x10000000 0x43000000 0x06 0x00 0x06 0x00 0x02 0x00>;
			bus-range = <0x00 0xff>;
			interrupt-map-mask = <0x00 0x00 0x00 0x07>;
			interrupt-map = <0x00 0x00 0x00 0x01 0x1c 0x01 0x00 0x00 0x00 0x02 0x1c 0x02 0x00 0x00 0x00 0x03 0x1c 0x03 0x00 0x00 0x00 0x04 0x1c 0x04>;
			power-domains = <0x17 0x3b>;
			clocks = <0x04 0x17>;
			phandle = <0x1b>;

			legacy-interrupt-controller {
				interrupt-controller;
				#address-cells = <0x00>;
				#interrupt-cells = <0x01>;
				phandle = <0x1c>;
			};
		};

		spi@ff0f0000 {
			bootph-all;
			compatible = "xlnx,zynqmp-qspi-1.0";
			status = "disabled";
			clock-names = "ref_clk\0pclk";
			interrupts = <0x00 0x0f 0x04>;
			interrupt-parent = <0x05>;
			num-cs = <0x01>;
			reg = <0x00 0xff0f0000 0x00 0x1000 0x00 0xc0000000 0x00 0x8000000>;
			#address-cells = <0x01>;
			#size-cells = <0x00>;
			power-domains = <0x17 0x2d>;
			clocks = <0x04 0x35 0x04 0x1f>;
			phandle = <0x7b>;
		};

		phy@fd400000 {
			compatible = "xlnx,zynqmp-psgtr-v1.1";
			status = "okay";
			reg = <0x00 0xfd400000 0x00 0x40000 0x00 0xfd3d0000 0x00 0x1000>;
			reg-names = "serdes\0siou";
			#phy-cells = <0x04>;
			clocks = <0x1d 0x1e>;
			clock-names = "ref0\0ref1";
			phandle = <0x28>;
		};

		rtc@ffa60000 {
			compatible = "xlnx,zynqmp-rtc";
			status = "okay";
			reg = <0x00 0xffa60000 0x00 0x100>;
			interrupt-parent = <0x05>;
			interrupts = <0x00 0x1a 0x04 0x00 0x1b 0x04>;
			interrupt-names = "alarm\0sec";
			calibration = <0x7fff>;
			phandle = <0x7c>;
		};

		ahci@fd0c0000 {
			compatible = "ceva,ahci-1v84";
			status = "disabled";
			reg = <0x00 0xfd0c0000 0x00 0x2000>;
			interrupt-parent = <0x05>;
			interrupts = <0x00 0x85 0x04>;
			power-domains = <0x17 0x1c>;
			resets = <0x16 0x10>;
			clocks = <0x04 0x16>;
			phandle = <0x7d>;
		};

		mmc@ff160000 {
			bootph-all;
			compatible = "xlnx,zynqmp-8.9a\0arasan,sdhci-8.9a";
			status = "okay";
			interrupt-parent = <0x05>;
			interrupts = <0x00 0x30 0x04>;
			reg = <0x00 0xff160000 0x00 0x1000>;
			clock-names = "clk_xin\0clk_ahb";
			#clock-cells = <0x01>;
			clock-output-names = "clk_out_sd0\0clk_in_sd0";
			power-domains = <0x17 0x27>;
			resets = <0x16 0x26>;
			clocks = <0x04 0x36 0x04 0x1f>;
			assigned-clocks = <0x04 0x36>;
			no-1-8-v;
			disable-wp;
			pinctrl-names = "default";
			pinctrl-0 = <0x1f>;
			xlnx,mio-bank = <0x00>;
			phandle = <0x7e>;
		};

		mmc@ff170000 {
			bootph-all;
			compatible = "xlnx,zynqmp-8.9a\0arasan,sdhci-8.9a";
			status = "okay";
			interrupt-parent = <0x05>;
			interrupts = <0x00 0x31 0x04>;
			reg = <0x00 0xff170000 0x00 0x1000>;
			clock-names = "clk_xin\0clk_ahb";
			#clock-cells = <0x01>;
			clock-output-names = "clk_out_sd1\0clk_in_sd1";
			power-domains = <0x17 0x28>;
			resets = <0x16 0x27>;
			clocks = <0x04 0x37 0x04 0x1f>;
			assigned-clocks = <0x04 0x37>;
			bus-width = <0x04>;
			pinctrl-names = "default";
			pinctrl-0 = <0x20>;
			xlnx,mio-bank = <0x00>;
			non-removable;
			disable-wp;
			no-sd;
			cap-mmc-hw-reset;
			cap-power-off-card;
			mmc-pwrseq = <0x21>;
			vqmmc-supply = <0x22>;
			#address-cells = <0x01>;
			#size-cells = <0x00>;
			phandle = <0x7f>;

			wifi@2 {
				compatible = "ti,wl1831";
				reg = <0x02>;
				interrupt-parent = <0x1a>;
				interrupts = <0x4c 0x01>;
				phandle = <0x80>;
			};
		};

		iommu@fd800000 {
			compatible = "arm,mmu-500";
			reg = <0x00 0xfd800000 0x00 0x20000>;
			#iommu-cells = <0x01>;
			status = "disabled";
			#global-interrupts = <0x01>;
			interrupt-parent = <0x05>;
			interrupts = <0x00 0x9b 0x04 0x00 0x9b 0x04 0x00 0x9b 0x04 0x00 0x9b 0x04 0x00 0x9b 0x04 0x00 0x9b 0x04 0x00 0x9b 0x04 0x00 0x9b 0x04 0x00 0x9b 0x04 0x00 0x9b 0x04 0x00 0x9b 0x04 0x00 0x9b 0x04 0x00 0x9b 0x04 0x00 0x9b 0x04 0x00 0x9b 0x04 0x00 0x9b 0x04 0x00 0x9b 0x04>;
			phandle = <0x81>;
		};

		spi@ff040000 {
			compatible = "cdns,spi-r1p6";
			status = "okay";
			interrupt-parent = <0x05>;
			interrupts = <0x00 0x13 0x04>;
			reg = <0x00 0xff040000 0x00 0x1000>;
			clock-names = "ref_clk\0pclk";
			#address-cells = <0x01>;
			#size-cells = <0x00>;
			power-domains = <0x17 0x23>;
			clocks = <0x04 0x3a 0x04 0x1f>;
			label = "LS-SPI0";
			num-cs = <0x01>;
			pinctrl-names = "default";
			pinctrl-0 = <0x23>;
			phandle = <0x82>;
		};

		spi@ff050000 {
			compatible = "cdns,spi-r1p6";
			status = "okay";
			interrupt-parent = <0x05>;
			interrupts = <0x00 0x14 0x04>;
			reg = <0x00 0xff050000 0x00 0x1000>;
			clock-names = "ref_clk\0pclk";
			#address-cells = <0x01>;
			#size-cells = <0x00>;
			power-domains = <0x17 0x24>;
			clocks = <0x04 0x3b 0x04 0x1f>;
			label = "HS-SPI1";
			num-cs = <0x01>;
			pinctrl-names = "default";
			pinctrl-0 = <0x24>;
			phandle = <0x83>;
		};

		timer@ff110000 {
			compatible = "cdns,ttc";
			status = "disabled";
			interrupt-parent = <0x05>;
			interrupts = <0x00 0x24 0x04 0x00 0x25 0x04 0x00 0x26 0x04>;
			reg = <0x00 0xff110000 0x00 0x1000>;
			timer-width = <0x20>;
			power-domains = <0x17 0x18>;
			clocks = <0x04 0x1f>;
			phandle = <0x84>;
		};

		timer@ff120000 {
			compatible = "cdns,ttc";
			status = "disabled";
			interrupt-parent = <0x05>;
			interrupts = <0x00 0x27 0x04 0x00 0x28 0x04 0x00 0x29 0x04>;
			reg = <0x00 0xff120000 0x00 0x1000>;
			timer-width = <0x20>;
			power-domains = <0x17 0x19>;
			clocks = <0x04 0x1f>;
			phandle = <0x85>;
		};

		timer@ff130000 {
			compatible = "cdns,ttc";
			status = "disabled";
			interrupt-parent = <0x05>;
			interrupts = <0x00 0x2a 0x04 0x00 0x2b 0x04 0x00 0x2c 0x04>;
			reg = <0x00 0xff130000 0x00 0x1000>;
			timer-width = <0x20>;
			power-domains = <0x17 0x1a>;
			clocks = <0x04 0x1f>;
			phandle = <0x86>;
		};

		timer@ff140000 {
			compatible = "cdns,ttc";
			status = "disabled";
			interrupt-parent = <0x05>;
			interrupts = <0x00 0x2d 0x04 0x00 0x2e 0x04 0x00 0x2f 0x04>;
			reg = <0x00 0xff140000 0x00 0x1000>;
			timer-width = <0x20>;
			power-domains = <0x17 0x1b>;
			clocks = <0x04 0x1f>;
			phandle = <0x87>;
		};

		serial@ff000000 {
			bootph-all;
			compatible = "xlnx,zynqmp-uart\0cdns,uart-r1p12";
			status = "okay";
			interrupt-parent = <0x05>;
			interrupts = <0x00 0x15 0x04>;
			reg = <0x00 0xff000000 0x00 0x1000>;
			clock-names = "uart_clk\0pclk";
			power-domains = <0x17 0x21>;
			resets = <0x16 0x22>;
			clocks = <0x04 0x38 0x04 0x1f>;
			assigned-clocks = <0x04 0x38>;
			pinctrl-names = "default";
			pinctrl-0 = <0x25>;
			phandle = <0x88>;

			bluetooth {
				compatible = "ti,wl1831-st";
				enable-gpios = <0x1a 0x08 0x00>;
			};
		};

		serial@ff010000 {
			bootph-all;
			compatible = "xlnx,zynqmp-uart\0cdns,uart-r1p12";
			status = "okay";
			interrupt-parent = <0x05>;
			interrupts = <0x00 0x16 0x04>;
			reg = <0x00 0xff010000 0x00 0x1000>;
			clock-names = "uart_clk\0pclk";
			power-domains = <0x17 0x22>;
			resets = <0x16 0x23>;
			clocks = <0x04 0x39 0x04 0x1f>;
			assigned-clocks = <0x04 0x39>;
			pinctrl-names = "default";
			pinctrl-0 = <0x26>;
			phandle = <0x89>;
		};

		usb@ff9d0000 {
			#address-cells = <0x02>;
			#size-cells = <0x02>;
			status = "okay";
			compatible = "xlnx,zynqmp-dwc3";
			reg = <0x00 0xff9d0000 0x00 0x100>;
			clock-names = "bus_clk\0ref_clk";
			power-domains = <0x17 0x16>;
			resets = <0x16 0x3b 0x16 0x3d 0x16 0x3f>;
			reset-names = "usb_crst\0usb_hibrst\0usb_apbrst";
			ranges;
			clocks = <0x04 0x20 0x04 0x22>;
			assigned-clocks = <0x04 0x20 0x04 0x22>;
			pinctrl-names = "default";
			pinctrl-0 = <0x27>;
			phy-names = "usb3-phy";
			phys = <0x28 0x02 0x04 0x00 0x00>;
			phandle = <0x8a>;

			usb@fe200000 {
				compatible = "snps,dwc3";
				status = "okay";
				reg = <0x00 0xfe200000 0x00 0x40000>;
				interrupt-parent = <0x05>;
				interrupt-names = "host\0peripheral\0otg\0wakeup";
				interrupts = <0x00 0x41 0x04 0x00 0x41 0x04 0x00 0x45 0x04 0x00 0x4b 0x04>;
				clock-names = "ref";
				snps,quirk-frame-length-adjustment = <0x20>;
				snps,resume-hs-terminations;
				clocks = <0x04 0x22>;
				dr_mode = "peripheral";
				maximum-speed = "super-speed";
				phandle = <0x8b>;
			};
		};

		usb@ff9e0000 {
			#address-cells = <0x02>;
			#size-cells = <0x02>;
			status = "okay";
			compatible = "xlnx,zynqmp-dwc3";
			reg = <0x00 0xff9e0000 0x00 0x100>;
			clock-names = "bus_clk\0ref_clk";
			power-domains = <0x17 0x17>;
			resets = <0x16 0x3c 0x16 0x3e 0x16 0x40>;
			reset-names = "usb_crst\0usb_hibrst\0usb_apbrst";
			ranges;
			clocks = <0x04 0x21 0x04 0x22>;
			assigned-clocks = <0x04 0x21 0x04 0x22>;
			pinctrl-names = "default";
			pinctrl-0 = <0x29>;
			phy-names = "usb3-phy";
			phys = <0x28 0x03 0x04 0x01 0x00>;
			reset-gpios = <0x2a 0x01 0x01>;
			phandle = <0x8c>;

			usb@fe300000 {
				compatible = "snps,dwc3";
				status = "okay";
				reg = <0x00 0xfe300000 0x00 0x40000>;
				interrupt-parent = <0x05>;
				interrupt-names = "host\0peripheral\0otg\0wakeup";
				interrupts = <0x00 0x46 0x04 0x00 0x46 0x04 0x00 0x4a 0x04 0x00 0x4c 0x04>;
				clock-names = "ref";
				snps,quirk-frame-length-adjustment = <0x20>;
				snps,resume-hs-terminations;
				clocks = <0x04 0x22>;
				dr_mode = "host";
				maximum-speed = "super-speed";
				phandle = <0x8d>;
			};
		};

		watchdog@fd4d0000 {
			compatible = "cdns,wdt-r1p2";
			status = "okay";
			interrupt-parent = <0x05>;
			interrupts = <0x00 0x71 0x01>;
			reg = <0x00 0xfd4d0000 0x00 0x1000>;
			timeout-sec = <0x3c>;
			reset-on-timeout;
			clocks = <0x04 0x4b>;
			phandle = <0x8e>;
		};

		watchdog@ff150000 {
			compatible = "cdns,wdt-r1p2";
			status = "disabled";
			interrupt-parent = <0x05>;
			interrupts = <0x00 0x34 0x01>;
			reg = <0x00 0xff150000 0x00 0x1000>;
			timeout-sec = <0x0a>;
			clocks = <0x04 0x70>;
			phandle = <0x8f>;
		};

		ams@ffa50000 {
			compatible = "xlnx,zynqmp-ams";
			interrupt-parent = <0x05>;
			interrupts = <0x00 0x38 0x04>;
			reg = <0x00 0xffa50000 0x00 0x800>;
			#address-cells = <0x01>;
			#size-cells = <0x01>;
			#io-channel-cells = <0x01>;
			ranges = <0x00 0x00 0xffa50800 0x800>;
			clocks = <0x04 0x46>;
			phandle = <0x11>;

			ams-ps@0 {
				compatible = "xlnx,zynqmp-ams-ps";
				status = "okay";
				reg = <0x00 0x400>;
				phandle = <0x90>;
			};

			ams-pl@400 {
				compatible = "xlnx,zynqmp-ams-pl";
				status = "disabled";
				reg = <0x400 0x400>;
				phandle = <0x91>;
			};
		};

		dma-controller@fd4c0000 {
			compatible = "xlnx,zynqmp-dpdma";
			status = "okay";
			reg = <0x00 0xfd4c0000 0x00 0x1000>;
			interrupts = <0x00 0x7a 0x04>;
			interrupt-parent = <0x05>;
			clock-names = "axi_clk";
			power-domains = <0x17 0x29>;
			#dma-cells = <0x01>;
			clocks = <0x04 0x14>;
			assigned-clocks = <0x04 0x14>;
			phandle = <0x2b>;
		};

		display@fd4a0000 {
			bootph-all;
			compatible = "xlnx,zynqmp-dpsub-1.7";
			status = "okay";
			reg = <0x00 0xfd4a0000 0x00 0x1000 0x00 0xfd4aa000 0x00 0x1000 0x00 0xfd4ab000 0x00 0x1000 0x00 0xfd4ac000 0x00 0x1000>;
			reg-names = "dp\0blend\0av_buf\0aud";
			interrupts = <0x00 0x77 0x04>;
			interrupt-parent = <0x05>;
			clock-names = "dp_apb_clk\0dp_aud_clk\0dp_vtc_pixel_clk_in";
			power-domains = <0x17 0x29>;
			resets = <0x16 0x03>;
			dma-names = "vid0\0vid1\0vid2\0gfx0\0aud0\0aud1";
			dmas = <0x2b 0x00 0x2b 0x01 0x2b 0x02 0x2b 0x03 0x2b 0x04 0x2b 0x05>;
			clocks = <0x04 0x1c 0x04 0x11 0x04 0x10>;
			assigned-clocks = <0x04 0x12 0x04 0x11 0x04 0x10>;
			phy-names = "dp-phy0\0dp-phy1";
			phys = <0x28 0x01 0x06 0x00 0x01 0x28 0x00 0x06 0x01 0x01>;
			phandle = <0x92>;

			ports {
				#address-cells = <0x01>;
				#size-cells = <0x00>;

				port@0 {
					reg = <0x00>;
					phandle = <0x93>;
				};

				port@1 {
					reg = <0x01>;
					phandle = <0x94>;
				};

				port@2 {
					reg = <0x02>;
					phandle = <0x95>;
				};

				port@3 {
					reg = <0x03>;
					phandle = <0x96>;
				};

				port@4 {
					reg = <0x04>;
					phandle = <0x97>;
				};

				port@5 {
					reg = <0x05>;
					phandle = <0x98>;

					endpoint {
						remote-endpoint = <0x2c>;
						phandle = <0x2e>;
					};
				};
			};
		};
	};

	pss-ref-clk {
		bootph-all;
		compatible = "fixed-clock";
		#clock-cells = <0x00>;
		clock-frequency = <0x1fca055>;
		clock-output-names = "pss_ref_clk";
		phandle = <0x0b>;
	};

	video-clk {
		bootph-all;
		compatible = "fixed-clock";
		#clock-cells = <0x00>;
		clock-frequency = <0x19bfcc0>;
		clock-output-names = "video_clk";
		phandle = <0x0c>;
	};

	pss-alt-ref-clk {
		bootph-all;
		compatible = "fixed-clock";
		#clock-cells = <0x00>;
		clock-frequency = <0x00>;
		clock-output-names = "pss_alt_ref_clk";
		phandle = <0x0d>;
	};

	gt-crx-ref-clk {
		bootph-all;
		compatible = "fixed-clock";
		#clock-cells = <0x00>;
		clock-frequency = <0x66ff300>;
		clock-output-names = "gt_crx_ref_clk";
		phandle = <0x0f>;
	};

	aux-ref-clk {
		bootph-all;
		compatible = "fixed-clock";
		#clock-cells = <0x00>;
		clock-frequency = <0x19bfcc0>;
		clock-output-names = "aux_ref_clk";
		phandle = <0x0e>;
	};

	aliases {
		i2c0 = "/axi/i2c@ff030000";
		rtc0 = "/axi/rtc@ffa60000";
		serial0 = "/axi/serial@ff010000";
		serial1 = "/axi/serial@ff000000";
		serial2 = "/dcc";
		spi0 = "/axi/spi@ff040000";
		spi1 = "/axi/spi@ff050000";
		usb0 = "/axi/usb@ff9d0000";
		usb1 = "/axi/usb@ff9e0000";
		mmc0 = "/axi/mmc@ff160000";
		mmc1 = "/axi/mmc@ff170000";
	};

	chosen {
		bootargs = "earlycon";
		stdout-path = "serial0:115200n8";
	};

	memory@0 {
		device_type = "memory";
		reg = <0x00 0x00 0x00 0x80000000>;
	};

	gpio-keys {
		compatible = "gpio-keys";
		autorepeat;

		switch-4 {
			label = "sw4";
			gpios = <0x1a 0x17 0x01>;
			linux,code = <0x74>;
			wakeup-source;
			autorepeat;
		};
	};

	iio-hwmon {
		compatible = "iio-hwmon";
		io-channels = <0x11 0x00 0x11 0x01 0x11 0x02 0x11 0x03 0x11 0x04 0x11 0x05 0x11 0x06 0x11 0x07 0x11 0x08 0x11 0x09 0x11 0x0a 0x11 0x0b 0x11 0x0c>;
	};

	leds {
		compatible = "gpio-leds";

		led-ds2 {
			label = "ds2";
			gpios = <0x1a 0x14 0x00>;
			linux,default-trigger = "heartbeat";
		};

		led-ds3 {
			label = "ds3";
			gpios = <0x1a 0x13 0x00>;
			linux,default-trigger = "phy0tx";
			default-state = "off";
		};

		led-ds4 {
			label = "ds4";
			gpios = <0x1a 0x12 0x00>;
			linux,default-trigger = "phy0rx";
			default-state = "off";
		};

		led-ds5 {
			label = "ds5";
			gpios = <0x1a 0x11 0x00>;
			linux,default-trigger = "bluetooth-power";
		};

		led-vbus-det {
			label = "vbus_det";
			gpios = <0x1a 0x19 0x00>;
			default-state = "on";
		};
	};

	fixedregulator-mmcsdio {
		compatible = "regulator-fixed";
		regulator-name = "wmmcsdio_fixed";
		regulator-min-microvolt = <0x325aa0>;
		regulator-max-microvolt = <0x325aa0>;
		regulator-always-on;
		regulator-boot-on;
		phandle = <0x22>;
	};

	sdio-pwrseq {
		compatible = "mmc-pwrseq-simple";
		reset-gpios = <0x1a 0x07 0x01>;
		post-power-on-delay-ms = <0x0a>;
		phandle = <0x21>;
	};

	ina226 {
		compatible = "iio-hwmon";
		io-channels = <0x2d 0x00 0x2d 0x01 0x2d 0x02 0x2d 0x03>;
	};

	si5335-0 {
		compatible = "fixed-clock";
		#clock-cells = <0x00>;
		clock-frequency = <0x18cba80>;
		phandle = <0x1d>;
	};

	si5335-1 {
		compatible = "fixed-clock";
		#clock-cells = <0x00>;
		clock-frequency = <0x19bfcc0>;
		phandle = <0x1e>;
	};

	dpcon {
		compatible = "dp-connector";
		label = "P11";
		type = "full-size";

		port {

			endpoint {
				remote-endpoint = <0x2e>;
				phandle = <0x2c>;
			};
		};
	};

	amba_pl@0 {
		#address-cells = <0x02>;
		#size-cells = <0x02>;
		compatible = "simple-bus";
		ranges;
		phandle = <0x99>;
	};

	__symbols__ {
		cpu0 = "/cpus/cpu@0";
		cpu1 = "/cpus/cpu@1";
		cpu2 = "/cpus/cpu@2";
		cpu3 = "/cpus/cpu@3";
		L2 = "/cpus/l2-cache";
		CPU_SLEEP_0 = "/cpus/idle-states/cpu-sleep-0";
		cpu_opp_table = "/opp-table-cpu";
		rproc_0_fw_image = "/reserved-memory/memory@3ed00000";
		rproc_1_fw_image = "/reserved-memory/memory@3ef00000";
		zynqmp_ipi = "/zynqmp-ipi";
		ipi_mailbox_pmu1 = "/zynqmp-ipi/mailbox@ff9905c0";
		dcc = "/dcc";
		optee = "/firmware/optee";
		zynqmp_firmware = "/firmware/zynqmp-firmware";
		zynqmp_power = "/firmware/zynqmp-firmware/power-management";
		soc_revision = "/firmware/zynqmp-firmware/soc-nvmem/nvmem-layout/soc-revision@0";
		efuse_dna = "/firmware/zynqmp-firmware/soc-nvmem/nvmem-layout/efuse-dna@c";
		efuse_usr0 = "/firmware/zynqmp-firmware/soc-nvmem/nvmem-layout/efuse-usr0@20";
		efuse_usr1 = "/firmware/zynqmp-firmware/soc-nvmem/nvmem-layout/efuse-usr1@24";
		efuse_usr2 = "/firmware/zynqmp-firmware/soc-nvmem/nvmem-layout/efuse-usr2@28";
		efuse_usr3 = "/firmware/zynqmp-firmware/soc-nvmem/nvmem-layout/efuse-usr3@2c";
		efuse_usr4 = "/firmware/zynqmp-firmware/soc-nvmem/nvmem-layout/efuse-usr4@30";
		efuse_usr5 = "/firmware/zynqmp-firmware/soc-nvmem/nvmem-layout/efuse-usr5@34";
		efuse_usr6 = "/firmware/zynqmp-firmware/soc-nvmem/nvmem-layout/efuse-usr6@38";
		efuse_usr7 = "/firmware/zynqmp-firmware/soc-nvmem/nvmem-layout/efuse-usr7@3c";
		efuse_miscusr = "/firmware/zynqmp-firmware/soc-nvmem/nvmem-layout/efuse-miscusr@40";
		efuse_chash = "/firmware/zynqmp-firmware/soc-nvmem/nvmem-layout/efuse-chash@50";
		efuse_pufmisc = "/firmware/zynqmp-firmware/soc-nvmem/nvmem-layout/efuse-pufmisc@54";
		efuse_sec = "/firmware/zynqmp-firmware/soc-nvmem/nvmem-layout/efuse-sec@58";
		efuse_spkid = "/firmware/zynqmp-firmware/soc-nvmem/nvmem-layout/efuse-spkid@5c";
		efuse_aeskey = "/firmware/zynqmp-firmware/soc-nvmem/nvmem-layout/efuse-aeskey@60";
		efuse_ppk0hash = "/firmware/zynqmp-firmware/soc-nvmem/nvmem-layout/efuse-ppk0hash@a0";
		efuse_ppk1hash = "/firmware/zynqmp-firmware/soc-nvmem/nvmem-layout/efuse-ppk1hash@d0";
		efuse_pufuser = "/firmware/zynqmp-firmware/soc-nvmem/nvmem-layout/efuse-pufuser@100";
		zynqmp_pcap = "/firmware/zynqmp-firmware/pcap";
		zynqmp_reset = "/firmware/zynqmp-firmware/reset-controller";
		pinctrl0 = "/firmware/zynqmp-firmware/pinctrl";
		pinctrl_i2c1_default = "/firmware/zynqmp-firmware/pinctrl/i2c1-default";
		pinctrl_i2c1_gpio = "/firmware/zynqmp-firmware/pinctrl/i2c1-gpio-grp";
		pinctrl_sdhci0_default = "/firmware/zynqmp-firmware/pinctrl/sdhci0-default";
		pinctrl_sdhci1_default = "/firmware/zynqmp-firmware/pinctrl/sdhci1-default";
		pinctrl_spi0_default = "/firmware/zynqmp-firmware/pinctrl/spi0-default";
		pinctrl_spi1_default = "/firmware/zynqmp-firmware/pinctrl/spi1-default";
		pinctrl_uart0_default = "/firmware/zynqmp-firmware/pinctrl/uart0-default";
		pinctrl_uart1_default = "/firmware/zynqmp-firmware/pinctrl/uart1-default";
		pinctrl_usb0_default = "/firmware/zynqmp-firmware/pinctrl/usb0-default";
		pinctrl_usb1_default = "/firmware/zynqmp-firmware/pinctrl/usb1-default";
		modepin_gpio = "/firmware/zynqmp-firmware/gpio";
		zynqmp_clk = "/firmware/zynqmp-firmware/clock-controller";
		fpga_full = "/fpga-region";
		ams = "/ams";
		tsens_apu = "/thermal-sensor-apu";
		tsens_rpu = "/thermal-sensor-rpu";
		tsens_pl = "/thermal-sensor-pl";
		apu_passive = "/thermal-zones/apu-thermal/trips/passive";
		apu_critical = "/thermal-zones/apu-thermal/trips/critical";
		amba = "/axi";
		can0 = "/axi/can@ff060000";
		can1 = "/axi/can@ff070000";
		cci = "/axi/cci@fd6e0000";
		cpu0_debug = "/axi/debug@fec10000";
		cpu1_debug = "/axi/debug@fed10000";
		cpu2_debug = "/axi/debug@fee10000";
		cpu3_debug = "/axi/debug@fef10000";
		fpd_dma_chan1 = "/axi/dma-controller@fd500000";
		fpd_dma_chan2 = "/axi/dma-controller@fd510000";
		fpd_dma_chan3 = "/axi/dma-controller@fd520000";
		fpd_dma_chan4 = "/axi/dma-controller@fd530000";
		fpd_dma_chan5 = "/axi/dma-controller@fd540000";
		fpd_dma_chan6 = "/axi/dma-controller@fd550000";
		fpd_dma_chan7 = "/axi/dma-controller@fd560000";
		fpd_dma_chan8 = "/axi/dma-controller@fd570000";
		gic = "/axi/interrupt-controller@f9010000";
		gpu = "/axi/gpu@fd4b0000";
		lpd_dma_chan1 = "/axi/dma-controller@ffa80000";
		lpd_dma_chan2 = "/axi/dma-controller@ffa90000";
		lpd_dma_chan3 = "/axi/dma-controller@ffaa0000";
		lpd_dma_chan4 = "/axi/dma-controller@ffab0000";
		lpd_dma_chan5 = "/axi/dma-controller@ffac0000";
		lpd_dma_chan6 = "/axi/dma-controller@ffad0000";
		lpd_dma_chan7 = "/axi/dma-controller@ffae0000";
		lpd_dma_chan8 = "/axi/dma-controller@ffaf0000";
		mc = "/axi/memory-controller@fd070000";
		nand0 = "/axi/nand-controller@ff100000";
		gem0 = "/axi/ethernet@ff0b0000";
		gem1 = "/axi/ethernet@ff0c0000";
		gem2 = "/axi/ethernet@ff0d0000";
		gem3 = "/axi/ethernet@ff0e0000";
		gpio = "/axi/gpio@ff0a0000";
		i2c0 = "/axi/i2c@ff020000";
		i2c1 = "/axi/i2c@ff030000";
		i2csw_0 = "/axi/i2c@ff030000/i2c-mux@75/i2c@0";
		i2csw_1 = "/axi/i2c@ff030000/i2c-mux@75/i2c@1";
		i2csw_2 = "/axi/i2c@ff030000/i2c-mux@75/i2c@2";
		i2csw_3 = "/axi/i2c@ff030000/i2c-mux@75/i2c@3";
		i2csw_4 = "/axi/i2c@ff030000/i2c-mux@75/i2c@4";
		pmic = "/axi/i2c@ff030000/i2c-mux@75/i2c@4/pmic@5e";
		i2csw_5 = "/axi/i2c@ff030000/i2c-mux@75/i2c@5";
		u35 = "/axi/i2c@ff030000/i2c-mux@75/i2c@5/ina226@40";
		i2csw_6 = "/axi/i2c@ff030000/i2c-mux@75/i2c@6";
		i2csw_7 = "/axi/i2c@ff030000/i2c-mux@75/i2c@7";
		ocm = "/axi/memory-controller@ff960000";
		perf_monitor_ocm = "/axi/perf-monitor@ffa00000";
		perf_monitor_ddr = "/axi/perf-monitor@fd0b0000";
		perf_monitor_cci = "/axi/perf-monitor@fd490000";
		perf_monitor_lpd = "/axi/perf-monitor@ffa10000";
		pcie = "/axi/pcie@fd0e0000";
		pcie_intc = "/axi/pcie@fd0e0000/legacy-interrupt-controller";
		qspi = "/axi/spi@ff0f0000";
		psgtr = "/axi/phy@fd400000";
		rtc = "/axi/rtc@ffa60000";
		sata = "/axi/ahci@fd0c0000";
		sdhci0 = "/axi/mmc@ff160000";
		sdhci1 = "/axi/mmc@ff170000";
		wlcore = "/axi/mmc@ff170000/wifi@2";
		smmu = "/axi/iommu@fd800000";
		spi0 = "/axi/spi@ff040000";
		spi1 = "/axi/spi@ff050000";
		ttc0 = "/axi/timer@ff110000";
		ttc1 = "/axi/timer@ff120000";
		ttc2 = "/axi/timer@ff130000";
		ttc3 = "/axi/timer@ff140000";
		uart0 = "/axi/serial@ff000000";
		uart1 = "/axi/serial@ff010000";
		usb0 = "/axi/usb@ff9d0000";
		dwc3_0 = "/axi/usb@ff9d0000/usb@fe200000";
		usb1 = "/axi/usb@ff9e0000";
		dwc3_1 = "/axi/usb@ff9e0000/usb@fe300000";
		watchdog0 = "/axi/watchdog@fd4d0000";
		lpd_watchdog = "/axi/watchdog@ff150000";
		xilinx_ams = "/axi/ams@ffa50000";
		ams_ps = "/axi/ams@ffa50000/ams-ps@0";
		ams_pl = "/axi/ams@ffa50000/ams-pl@400";
		zynqmp_dpdma = "/axi/dma-controller@fd4c0000";
		zynqmp_dpsub = "/axi/display@fd4a0000";
		live_video = "/axi/display@fd4a0000/ports/port@0";
		live_gfx = "/axi/display@fd4a0000/ports/port@1";
		live_audio = "/axi/display@fd4a0000/ports/port@2";
		out_video = "/axi/display@fd4a0000/ports/port@3";
		out_audio = "/axi/display@fd4a0000/ports/port@4";
		out_dp = "/axi/display@fd4a0000/ports/port@5";
		dpsub_dp_out = "/axi/display@fd4a0000/ports/port@5/endpoint";
		pss_ref_clk = "/pss-ref-clk";
		video_clk = "/video-clk";
		pss_alt_ref_clk = "/pss-alt-ref-clk";
		gt_crx_ref_clk = "/gt-crx-ref-clk";
		aux_ref_clk = "/aux-ref-clk";
		wmmcsdio_fixed = "/fixedregulator-mmcsdio";
		sdio_pwrseq = "/sdio-pwrseq";
		si5335_0 = "/si5335-0";
		si5335_1 = "/si5335-1";
		dpcon_in = "/dpcon/port/endpoint";
		amba_pl = "/amba_pl@0";
	};
};
